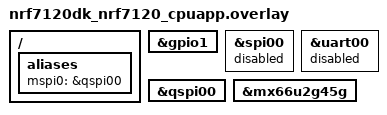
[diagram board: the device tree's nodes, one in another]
/*
 * Copyright (c) 2026 Nordic Semiconductor ASA
 *
 * SPDX-License-Identifier: Apache-2.0
 */

/ {
	aliases {
		mspi0 = &qspi00;
	};
};

&gpio1 {
	status = "okay";
};

&spi00 {
	status = "disabled";
};

&uart00 {
	status = "disabled";
};

&qspi00 {
	status = "okay";
};

&mx66u2g45g {
	status = "okay";
};
